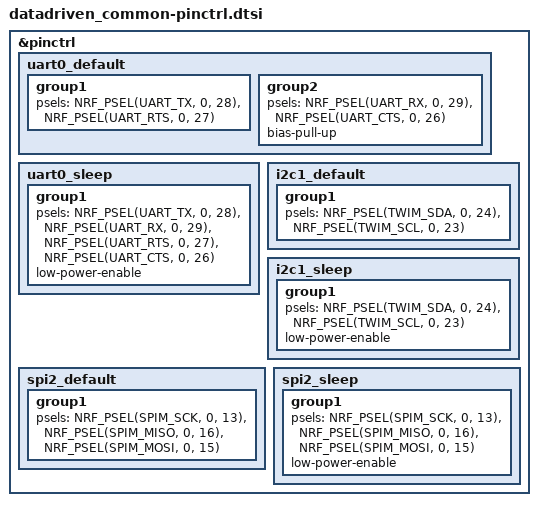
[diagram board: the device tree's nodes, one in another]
/*
 * Copyright (c) 2022 Nordic Semiconductor
 * SPDX-License-Identifier: Apache-2.0
 */

&pinctrl {
	uart0_default: uart0_default {
		group1 {
			psels = <NRF_PSEL(UART_TX, 0, 28)>,
				<NRF_PSEL(UART_RTS, 0, 27)>;
		};
		group2 {
			psels = <NRF_PSEL(UART_RX, 0, 29)>,
				<NRF_PSEL(UART_CTS, 0, 26)>;
			bias-pull-up;
		};
	};
	uart0_sleep: uart0_sleep {
		group1 {
			psels = <NRF_PSEL(UART_TX, 0, 28)>,
				<NRF_PSEL(UART_RX, 0, 29)>,
				<NRF_PSEL(UART_RTS, 0, 27)>,
				<NRF_PSEL(UART_CTS, 0, 26)>;
			low-power-enable;
		};
	};

	i2c1_default: i2c1_default {
		group1 {
			psels = <NRF_PSEL(TWIM_SDA, 0, 24)>,
				<NRF_PSEL(TWIM_SCL, 0, 23)>;
		};
	};

	i2c1_sleep: i2c1_sleep {
		group1 {
			psels = <NRF_PSEL(TWIM_SDA, 0, 24)>,
				<NRF_PSEL(TWIM_SCL, 0, 23)>;
			low-power-enable;
		};
	};

	spi2_default: spi2_default {
		group1 {
			psels = <NRF_PSEL(SPIM_SCK, 0, 13)>,
				<NRF_PSEL(SPIM_MISO, 0, 16)>,
				<NRF_PSEL(SPIM_MOSI, 0, 15)>;
		};
	};

	spi2_sleep: spi2_sleep {
		group1 {
			psels = <NRF_PSEL(SPIM_SCK, 0, 13)>,
				<NRF_PSEL(SPIM_MISO, 0, 16)>,
				<NRF_PSEL(SPIM_MOSI, 0, 15)>;
			low-power-enable;
		};
	};
};
